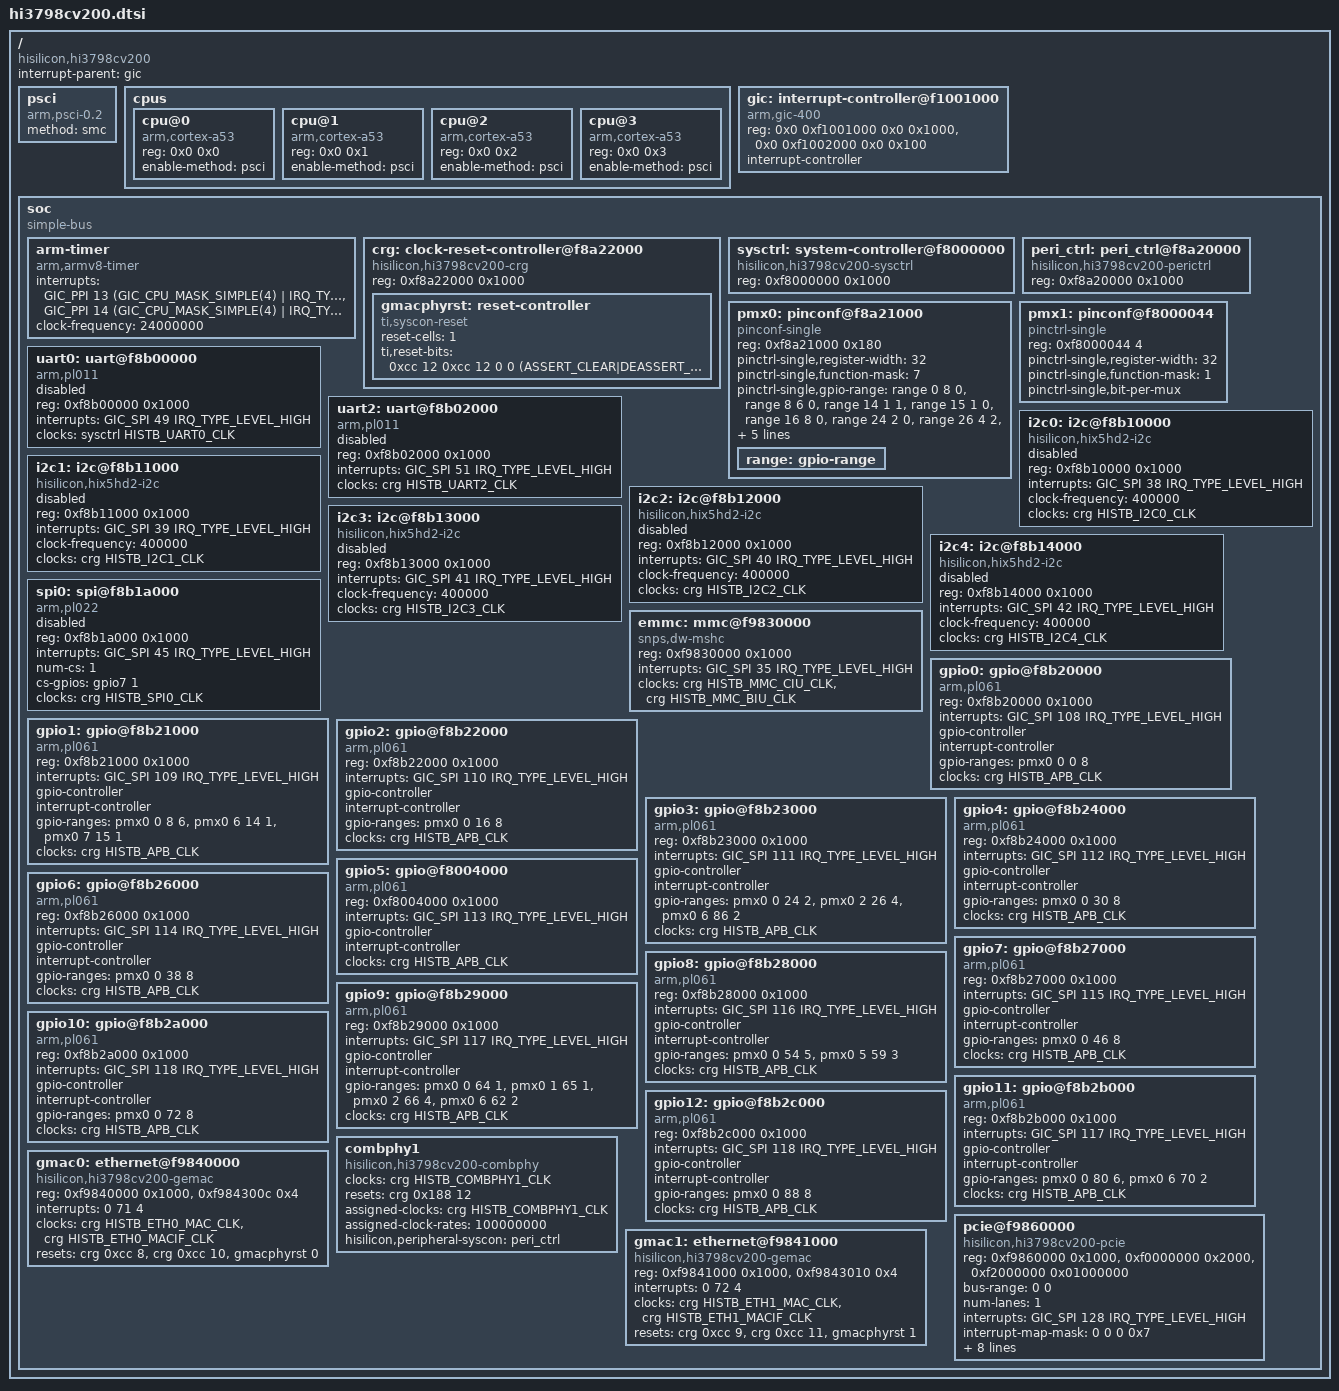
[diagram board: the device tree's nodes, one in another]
/*
 * DTS File for HiSilicon Hi3798cv200 SOC.
 *
 * Copyright (c) 2016 Hisilicon Limited.
 *
 *  This program is free software; you can redistribute it and/or modify
 *  it under the terms of the GNU General Public License version 2 as
 *  publishhed by the Free Software Foundation.
 */

#include <dt-bindings/interrupt-controller/arm-gic.h>
#include <dt-bindings/gpio/gpio.h>
#include <dt-bindings/clock/histb-clock.h>
#include <dt-bindings/reset/ti-syscon.h>

/ {
	compatible = "hisilicon,hi3798cv200";
	interrupt-parent = <&gic>;
	#address-cells = <2>;
	#size-cells = <2>;

	psci {
		compatible = "arm,psci-0.2";
		method = "smc";
	};

	cpus {
		#address-cells = <2>;
		#size-cells = <0>;

		cpu@0 {
			compatible = "arm,cortex-a53";
			device_type = "cpu";
			reg = <0x0 0x0>;
			enable-method = "psci";
		};

		cpu@1 {
			compatible = "arm,cortex-a53";
			device_type = "cpu";
			reg = <0x0 0x1>;
			enable-method = "psci";
		};

		cpu@2 {
			compatible = "arm,cortex-a53";
			device_type = "cpu";
			reg = <0x0 0x2>;
			enable-method = "psci";
		};

		cpu@3 {
			compatible = "arm,cortex-a53";
			device_type = "cpu";
			reg = <0x0 0x3>;
			enable-method = "psci";
		};
	};

	gic: interrupt-controller@f1001000 {
		compatible = "arm,gic-400";
		reg = <0x0 0xf1001000 0x0 0x1000>,  /*GICD*/
		      <0x0 0xf1002000 0x0 0x100>;   /*GICC*/
		#address-cells = <0>;
		#interrupt-cells = <3>;
		interrupt-controller;
	};

	soc {
		compatible = "simple-bus";
		#address-cells = <1>;
		#size-cells = <1>;
		ranges = <0x0 0x00000000 0x0 0xffffffff>;

		arm-timer {
			compatible = "arm,armv8-timer";
			interrupts = <GIC_PPI 13 (GIC_CPU_MASK_SIMPLE(4) | IRQ_TYPE_LEVEL_HIGH)>,
				     <GIC_PPI 14 (GIC_CPU_MASK_SIMPLE(4) | IRQ_TYPE_LEVEL_HIGH)>;
			clock-frequency = <24000000>;
		};

		crg: clock-reset-controller@f8a22000 {
			compatible = "hisilicon,hi3798cv200-crg", "simple-mfd";
			reg = <0xf8a22000 0x1000>;
			#clock-cells = <1>;
			#reset-cells = <2>;

			gmacphyrst: reset-controller {
				compatible = "ti,syscon-reset";
				reset-cells = <1>;
				ti,reset-bits = <
					0xcc 12 0xcc 12 0 0 (ASSERT_CLEAR|DEASSERT_SET|STATUS_NONE)  /* 0: gmac0-phy-rst */
					0xcc 13 0xcc 13 0 0 (ASSERT_CLEAR|DEASSERT_SET|STATUS_NONE)  /* 1: gmac1-phy-rst */
				>;
			};
		};

		sysctrl: system-controller@f8000000 {
			compatible = "hisilicon,hi3798cv200-sysctrl", "syscon";
			reg = <0xf8000000 0x1000>;
			#clock-cells = <1>;
			#reset-cells = <2>;
		};

		peri_ctrl: peri_ctrl@f8a20000 {
			compatible = "hisilicon,hi3798cv200-perictrl", "syscon";
			reg = <0xf8a20000 0x1000>;
		};

		pmx0: pinconf@f8a21000 {
			compatible = "pinconf-single";
			reg = <0xf8a21000 0x180>;
			pinctrl-single,register-width = <32>;
			pinctrl-single,function-mask = <7>;
			pinctrl-single,gpio-range = <
				&range 0  8 0  /* GPIO 0 */
				&range 8  6 0  /* GPIO 1 */
				&range 14 1 1
				&range 15 1 0
				&range 16 8 0  /* GPIO 2 */
				&range 24 2 0  /* GPIO 3 */
				&range 26 4 2
				&range 86 2 0
				&range 30 8 0  /* GPIO 4 */
				&range 38 8 0  /* GPIO 6 */
				&range 46 8 0  /* GPIO 7 */
				&range 54 5 0  /* GPIO 8 */
				&range 59 3 4
				&range 64 1 1  /* GPIO 9 */
				&range 65 1 0
				&range 66 4 2
				&range 62 2 4
				&range 72 8 0  /* GPIO 10 */
				&range 80 6 0  /* GPIO 11 */
				&range 70 2 0
				&range 88 8 0  /* GPIO 12 */
			>;

			range: gpio-range {
				#pinctrl-single,gpio-range-cells = <3>;
			};
		};

		pmx1: pinconf@f8000044 {
			compatible = "pinctrl-single";
			reg = <0xf8000044 4>;
			pinctrl-single,register-width = <32>;
			pinctrl-single,function-mask = <1>;
			pinctrl-single,bit-per-mux;
		};

		uart0: uart@f8b00000 {
			compatible = "arm,pl011", "arm,primecell";
			reg = <0xf8b00000 0x1000>;
			interrupts = <GIC_SPI 49 IRQ_TYPE_LEVEL_HIGH>;
			clocks = <&sysctrl HISTB_UART0_CLK>;
			clock-names = "apb_pclk";
			status = "disabled";
		};

		uart2: uart@f8b02000 {
			compatible = "arm,pl011", "arm,primecell";
			reg = <0xf8b02000 0x1000>;
			interrupts = <GIC_SPI 51 IRQ_TYPE_LEVEL_HIGH>;
			clocks = <&crg HISTB_UART2_CLK>;
			clock-names = "apb_pclk";
			status = "disabled";
		};

		i2c0: i2c@f8b10000 {
			compatible = "hisilicon,hix5hd2-i2c";
			reg = <0xf8b10000 0x1000>;
			#address-cells = <1>;
			#size-cells = <0>;
			interrupts = <GIC_SPI 38 IRQ_TYPE_LEVEL_HIGH>;
			clock-frequency = <400000>;
			clocks = <&crg HISTB_I2C0_CLK>;
			status = "disabled";
		};

		i2c1: i2c@f8b11000 {
			compatible = "hisilicon,hix5hd2-i2c";
			reg = <0xf8b11000 0x1000>;
			#address-cells = <1>;
			#size-cells = <0>;
			interrupts = <GIC_SPI 39 IRQ_TYPE_LEVEL_HIGH>;
			clock-frequency = <400000>;
			clocks = <&crg HISTB_I2C1_CLK>;
			status = "disabled";
		};

		i2c2: i2c@f8b12000 {
			compatible = "hisilicon,hix5hd2-i2c";
			reg = <0xf8b12000 0x1000>;
			#address-cells = <1>;
			#size-cells = <0>;
			interrupts = <GIC_SPI 40 IRQ_TYPE_LEVEL_HIGH>;
			clock-frequency = <400000>;
			clocks = <&crg HISTB_I2C2_CLK>;
			status = "disabled";
		};

		i2c3: i2c@f8b13000 {
			compatible = "hisilicon,hix5hd2-i2c";
			reg = <0xf8b13000 0x1000>;
			#address-cells = <1>;
			#size-cells = <0>;
			interrupts = <GIC_SPI 41 IRQ_TYPE_LEVEL_HIGH>;
			clock-frequency = <400000>;
			clocks = <&crg HISTB_I2C3_CLK>;
			status = "disabled";
		};

		i2c4: i2c@f8b14000 {
			compatible = "hisilicon,hix5hd2-i2c";
			reg = <0xf8b14000 0x1000>;
			#address-cells = <1>;
			#size-cells = <0>;
			interrupts = <GIC_SPI 42 IRQ_TYPE_LEVEL_HIGH>;
			clock-frequency = <400000>;
			clocks = <&crg HISTB_I2C4_CLK>;
			status = "disabled";
		};

		spi0: spi@f8b1a000 {
			compatible = "arm,pl022", "arm,primecell";
			reg = <0xf8b1a000 0x1000>;
			interrupts = <GIC_SPI 45 IRQ_TYPE_LEVEL_HIGH>;
			num-cs = <1>;
			cs-gpios = <&gpio7 1 0>;
			clocks = <&crg HISTB_SPI0_CLK>;
			clock-names = "apb_pclk";
			#address-cells = <1>;
			#size-cells = <0>;
			status = "disabled";
		};

		emmc: mmc@f9830000 {
			compatible = "snps,dw-mshc";
			reg = <0xf9830000 0x1000>;
			interrupts = <GIC_SPI 35 IRQ_TYPE_LEVEL_HIGH>;
			clocks = <&crg HISTB_MMC_CIU_CLK>,
				 <&crg HISTB_MMC_BIU_CLK>;
			clock-names = "ciu", "biu";
		};

		gpio0: gpio@f8b20000 {
			compatible = "arm,pl061", "arm,primecell";
			reg = <0xf8b20000 0x1000>;
			interrupts = <GIC_SPI 108 IRQ_TYPE_LEVEL_HIGH>;
			gpio-controller;
			#gpio-cells = <2>;
			interrupt-controller;
			#interrupt-cells = <2>;
			gpio-ranges = <&pmx0 0 0 8>;
			clocks = <&crg HISTB_APB_CLK>;
			clock-names = "apb_pclk";
		};

		gpio1: gpio@f8b21000 {
			compatible = "arm,pl061", "arm,primecell";
			reg = <0xf8b21000 0x1000>;
			interrupts = <GIC_SPI 109 IRQ_TYPE_LEVEL_HIGH>;
			gpio-controller;
			#gpio-cells = <2>;
			interrupt-controller;
			#interrupt-cells = <2>;
			gpio-ranges = <&pmx0 0 8 6 &pmx0 6 14 1 &pmx0 7 15 1>;
			clocks = <&crg HISTB_APB_CLK>;
			clock-names = "apb_pclk";
		};

		gpio2: gpio@f8b22000 {
			compatible = "arm,pl061", "arm,primecell";
			reg = <0xf8b22000 0x1000>;
			interrupts = <GIC_SPI 110 IRQ_TYPE_LEVEL_HIGH>;
			gpio-controller;
			#gpio-cells = <2>;
			interrupt-controller;
			#interrupt-cells = <2>;
			gpio-ranges = <&pmx0 0 16 8>;
			clocks = <&crg HISTB_APB_CLK>;
			clock-names = "apb_pclk";
		};

		gpio3: gpio@f8b23000 {
			compatible = "arm,pl061", "arm,primecell";
			reg = <0xf8b23000 0x1000>;
			interrupts = <GIC_SPI 111 IRQ_TYPE_LEVEL_HIGH>;
			gpio-controller;
			#gpio-cells = <2>;
			interrupt-controller;
			#interrupt-cells = <2>;
			gpio-ranges = <&pmx0 0 24 2 &pmx0 2 26 4 &pmx0 6 86 2>;
			clocks = <&crg HISTB_APB_CLK>;
			clock-names = "apb_pclk";
		};

		gpio4: gpio@f8b24000 {
			compatible = "arm,pl061", "arm,primecell";
			reg = <0xf8b24000 0x1000>;
			interrupts = <GIC_SPI 112 IRQ_TYPE_LEVEL_HIGH>;
			gpio-controller;
			#gpio-cells = <2>;
			interrupt-controller;
			#interrupt-cells = <2>;
			gpio-ranges = <&pmx0 0 30 8>;
			clocks = <&crg HISTB_APB_CLK>;
			clock-names = "apb_pclk";
		};

		gpio5: gpio@f8004000 {
			compatible = "arm,pl061", "arm,primecell";
			reg = <0xf8004000 0x1000>;
			interrupts = <GIC_SPI 113 IRQ_TYPE_LEVEL_HIGH>;
			gpio-controller;
			#gpio-cells = <2>;
			interrupt-controller;
			#interrupt-cells = <2>;
			clocks = <&crg HISTB_APB_CLK>;
			clock-names = "apb_pclk";
		};

		gpio6: gpio@f8b26000 {
			compatible = "arm,pl061", "arm,primecell";
			reg = <0xf8b26000 0x1000>;
			interrupts = <GIC_SPI 114 IRQ_TYPE_LEVEL_HIGH>;
			gpio-controller;
			#gpio-cells = <2>;
			interrupt-controller;
			#interrupt-cells = <2>;
			gpio-ranges = <&pmx0 0 38 8>;
			clocks = <&crg HISTB_APB_CLK>;
			clock-names = "apb_pclk";
		};

		gpio7: gpio@f8b27000 {
			compatible = "arm,pl061", "arm,primecell";
			reg = <0xf8b27000 0x1000>;
			interrupts = <GIC_SPI 115 IRQ_TYPE_LEVEL_HIGH>;
			gpio-controller;
			#gpio-cells = <2>;
			interrupt-controller;
			#interrupt-cells = <2>;
			gpio-ranges = <&pmx0 0 46 8>;
			clocks = <&crg HISTB_APB_CLK>;
			clock-names = "apb_pclk";
		};

		gpio8: gpio@f8b28000 {
			compatible = "arm,pl061", "arm,primecell";
			reg = <0xf8b28000 0x1000>;
			interrupts = <GIC_SPI 116 IRQ_TYPE_LEVEL_HIGH>;
			gpio-controller;
			#gpio-cells = <2>;
			interrupt-controller;
			#interrupt-cells = <2>;
			gpio-ranges = <&pmx0 0 54 5 &pmx0 5 59 3>;
			clocks = <&crg HISTB_APB_CLK>;
			clock-names = "apb_pclk";
		};

		gpio9: gpio@f8b29000 {
			compatible = "arm,pl061", "arm,primecell";
			reg = <0xf8b29000 0x1000>;
			interrupts = <GIC_SPI 117 IRQ_TYPE_LEVEL_HIGH>;
			gpio-controller;
			#gpio-cells = <2>;
			interrupt-controller;
			#interrupt-cells = <2>;
			gpio-ranges = <&pmx0 0 64 1 &pmx0 1 65 1 &pmx0 2 66 4 &pmx0 6 62 2>;
			clocks = <&crg HISTB_APB_CLK>;
			clock-names = "apb_pclk";
		};

		gpio10: gpio@f8b2a000 {
			compatible = "arm,pl061", "arm,primecell";
			reg = <0xf8b2a000 0x1000>;
			interrupts = <GIC_SPI 118 IRQ_TYPE_LEVEL_HIGH>;
			gpio-controller;
			#gpio-cells = <2>;
			interrupt-controller;
			#interrupt-cells = <2>;
			gpio-ranges = <&pmx0 0 72 8>;
			clocks = <&crg HISTB_APB_CLK>;
			clock-names = "apb_pclk";
		};

		gpio11: gpio@f8b2b000 {
			compatible = "arm,pl061", "arm,primecell";
			reg = <0xf8b2b000 0x1000>;
			interrupts = <GIC_SPI 117 IRQ_TYPE_LEVEL_HIGH>;
			gpio-controller;
			#gpio-cells = <2>;
			interrupt-controller;
			#interrupt-cells = <2>;
			gpio-ranges = <&pmx0 0 80 6 &pmx0 6 70 2>;
			clocks = <&crg HISTB_APB_CLK>;
			clock-names = "apb_pclk";
		};

		gpio12: gpio@f8b2c000 {
			compatible = "arm,pl061", "arm,primecell";
			reg = <0xf8b2c000 0x1000>;
			interrupts = <GIC_SPI 118 IRQ_TYPE_LEVEL_HIGH>;
			gpio-controller;
			#gpio-cells = <2>;
			interrupt-controller;
			#interrupt-cells = <2>;
			gpio-ranges = <&pmx0 0 88 8>;
			clocks = <&crg HISTB_APB_CLK>;
			clock-names = "apb_pclk";
		};

		combphy1: combphy1 {
			compatible = "hisilicon,hi3798cv200-combphy";
			#phy-cells = <1>;
			clocks = <&crg HISTB_COMBPHY1_CLK>;
			resets = <&crg 0x188 12>;
			assigned-clocks = <&crg HISTB_COMBPHY1_CLK>;
			assigned-clock-rates = <100000000>;
			hisilicon,peripheral-syscon = <&peri_ctrl>;
		};

		pcie@f9860000 {
			compatible = "hisilicon,hi3798cv200-pcie";
			reg = <0xf9860000 0x1000>, <0xf0000000 0x2000>,
				<0xf2000000 0x01000000>;
			reg-names = "control", "rc-dbi", "config";
			#address-cells = <3>;
			#size-cells = <2>;
			device_type = "pci";
			bus-range = <0 0>;
			num-lanes = <1>;
			ranges = <0x81000000 0x0 0x00000000 0xf4f00000 0x0 0x100000
				  0x82000000 0x0 0xf3000000 0xf3000000 0x0 0x01f00000>;
			interrupts = <GIC_SPI 128 IRQ_TYPE_LEVEL_HIGH>;
			interrupt-names = "msi";
			#interrupt-cells = <1>;
			interrupt-map-mask = <0 0 0 0x7>;
			interrupt-map = <0 0 0 1 &gic 0 131 4>;
			clocks = <&crg HISTB_PCIE_AUX_CLK>,
				 <&crg HISTB_PCIE_PIPE_CLK>,
				 <&crg HISTB_PCIE_SYS_CLK>,
				 <&crg HISTB_PCIE_BUS_CLK>;
			clock-names = "aux", "pipe", "sys", "bus";
			resets = <&crg 0x18c 6>, <&crg 0x18c 5>, <&crg 0x18c 4>;
			reset-names = "soft", "sys", "bus";
			phys = <&combphy1 0>;
			phy-names = "phy";
			hisilicon,power-gpios = <&gpio6 7 GPIO_ACTIVE_HIGH>;
			status = "ok";
		};

		gmac0: ethernet@f9840000 {
			compatible = "hisilicon,hi3798cv200-gemac", "hisilicon,hisi-gemac-v2";
			reg = <0xf9840000 0x1000>,<0xf984300c 0x4>;
			interrupts = <0 71 4>;
			clocks = <&crg HISTB_ETH0_MAC_CLK>,
					<&crg HISTB_ETH0_MACIF_CLK>;
			clock-names = "mac_core", "mac_ifc";
			resets = <&crg 0xcc 8>, <&crg 0xcc 10>, <&gmacphyrst 0>;
			reset-names = "mac_core", "mac_ifc", "phy";
		};

		gmac1: ethernet@f9841000 {
			compatible = "hisilicon,hi3798cv200-gemac", "hisilicon,hisi-gemac-v2";
			reg = <0xf9841000 0x1000>,<0xf9843010 0x4>;
			interrupts = <0 72 4>;
			clocks = <&crg HISTB_ETH1_MAC_CLK>,
					<&crg HISTB_ETH1_MACIF_CLK>;
			clock-names = "mac_core", "mac_ifc";
			resets = <&crg 0xcc 9>, <&crg 0xcc 11>, <&gmacphyrst 1>;
			reset-names = "mac_core", "mac_ifc", "phy";
		};
	};
};
